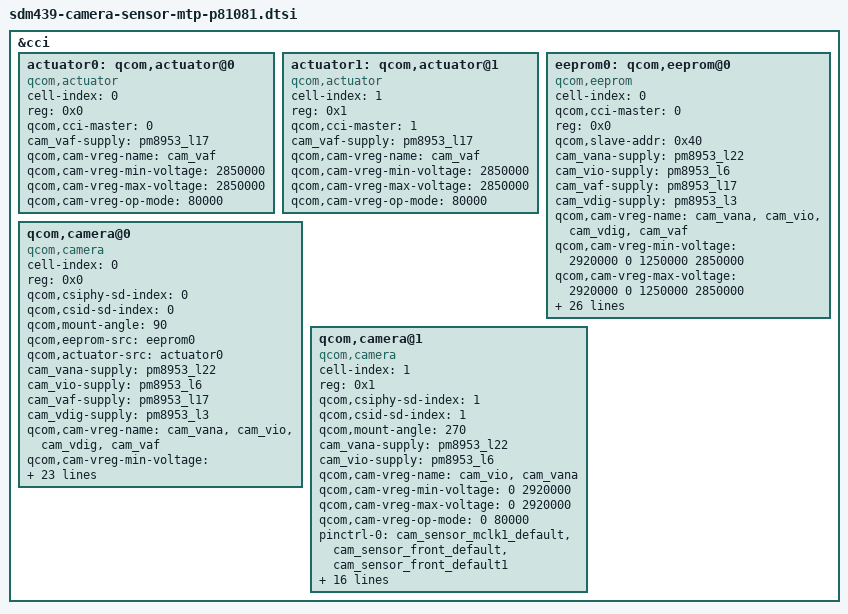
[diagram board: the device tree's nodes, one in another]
/*
 * Copyright (c) 2015-2016, 2018, The Linux Foundation. All rights reserved.
 *
 * This program is free software; you can redistribute it and/or modify
 * it under the terms of the GNU General Public License version 2 and
 * only version 2 as published by the Free Software Foundation.
 *
 * This program is distributed in the hope that it will be useful,
 * but WITHOUT ANY WARRANTY; without even the implied warranty of
 * MERCHANTABILITY or FITNESS FOR A PARTICULAR PURPOSE.  See the
 * GNU General Public License for more details.
 */

#include <dt-bindings/clock/msm-clocks-8952.h>

&cci {
	actuator0: qcom,actuator@0 {
		cell-index = <0>;
		reg = <0x0>;
		compatible = "qcom,actuator";
		qcom,cci-master = <0>;
		cam_vaf-supply = <&pm8953_l17>;
		qcom,cam-vreg-name = "cam_vaf";
		qcom,cam-vreg-min-voltage = <2850000>;
		qcom,cam-vreg-max-voltage = <2850000>;
		qcom,cam-vreg-op-mode = <80000>;
	};

	actuator1: qcom,actuator@1 {
		cell-index = <1>;
		reg = <0x1>;
		compatible = "qcom,actuator";
		qcom,cci-master = <1>;
		cam_vaf-supply = <&pm8953_l17>;
		qcom,cam-vreg-name = "cam_vaf";
		qcom,cam-vreg-min-voltage = <2850000>;
		qcom,cam-vreg-max-voltage = <2850000>;
		qcom,cam-vreg-op-mode = <80000>;
	};

	eeprom0: qcom,eeprom@0 {
		cell-index = <0>;
		compatible = "qcom,eeprom";
		qcom,cci-master = <0>;
		reg = <0x0>;
		qcom,slave-addr = <0x40>;
		cam_vana-supply = <&pm8953_l22>;
		cam_vio-supply = <&pm8953_l6>;
		cam_vaf-supply = <&pm8953_l17>;
		cam_vdig-supply = <&pm8953_l3>;
		qcom,cam-vreg-name = "cam_vana",
			"cam_vio", "cam_vdig", "cam_vaf";
		qcom,cam-vreg-min-voltage = <2920000 0 1250000 2850000>;
		qcom,cam-vreg-max-voltage = <2920000 0 1250000 2850000>;
		qcom,cam-vreg-op-mode = <80000 0 200000 100000>;
		pinctrl-names = "cam_default", "cam_suspend";
		pinctrl-0 = <&cam_sensor_mclk0_default
				&cam_sensor_rear_reset
			&cam_sensor_rear_vana>;
		pinctrl-1 = <&cam_sensor_mclk0_sleep
			&cam_sensor_rear_reset_sleep
			&cam_sensor_rear_vana_sleep>;
		gpios = <&tlmm 26 0>,
			<&tlmm 36 0>,
			<&tlmm 20 0>;
		qcom,gpio-reset = <1>;
		qcom,gpio-vana = <2>;
		qcom,gpio-req-tbl-num = <0 1 2>;
		qcom,gpio-req-tbl-flags = <1 0 0>;
		qcom,gpio-req-tbl-label = "CAMIF_MCLK0",
			"CAM_RESET0",
			"CAM_STANDBY0";
		qcom,cam-power-seq-type = "sensor_vreg", "sensor_vreg", "sensor_gpio" , "sensor_gpio" ,"sensor_clk", "sensor_gpio", "sensor_gpio";
		qcom,cam-power-seq-val = "cam_vana", "cam_gpio_vdig", "sensor_gpio_reset","sensor_gpio_standby", "sensor_cam_mclk", "sensor_gpio_reset","sensor_gpio_standby";
		qcom,cam-power-seq-cfg-val = <0 0 0 0 24000000 1 1>;
		qcom,cam-power-seq-delay = <0 0 1 1 5 5 5>;
		status = "ok";
		clocks = <&clock_gcc clk_mclk0_clk_src>,
			<&clock_gcc clk_gcc_camss_mclk0_clk>;
		clock-names = "cam_src_clk", "cam_clk";
		qcom,clock-rates = <24000000 0>;
	};
	qcom,camera@0 {
		cell-index = <0>;
		compatible = "qcom,camera";
		reg = <0x0>;
		qcom,csiphy-sd-index = <0>;
		qcom,csid-sd-index = <0>;
		qcom,mount-angle = <90>;
		//qcom,led-flash-src = <&led_flash0>;
		qcom,eeprom-src = <&eeprom0>;
		qcom,actuator-src = <&actuator0>;
		cam_vana-supply = <&pm8953_l22>;
		cam_vio-supply = <&pm8953_l6>;
		cam_vaf-supply = <&pm8953_l17>;
		cam_vdig-supply = <&pm8953_l3>;
		qcom,cam-vreg-name = "cam_vana",
			"cam_vio","cam_vdig", "cam_vaf";
		qcom,cam-vreg-min-voltage = <2920000 0 1250000 2850000>;
		qcom,cam-vreg-max-voltage = <2920000 0 1250000 2850000>;
		qcom,cam-vreg-op-mode = <80000 0 200000 100000>;
		pinctrl-names = "cam_default", "cam_suspend";
		pinctrl-0 = <&cam_sensor_mclk0_default
			&cam_sensor_rear_reset
			&cam_sensor_rear_standby>;
		pinctrl-1 = <&cam_sensor_mclk0_sleep
			&cam_sensor_rear_reset_sleep
			&cam_sensor_rear_standby_sleep>;
		gpios = <&tlmm 26 0>,
			<&tlmm 36 0>,
		       <&tlmm 20 0>;
		qcom,gpio-reset = <1>;
		qcom,gpio-standby = <2>;
		qcom,gpio-req-tbl-num = <0 1 2>;
		qcom,gpio-req-tbl-flags = <1 0 0>;
		qcom,gpio-req-tbl-label = "CAMIF_MCLK0",
			"CAM_RESET0",
			"CAM_STANDBY0";
		qcom,sensor-position = <0>;
		qcom,sensor-mode = <0>;
		qcom,cci-master = <0>;
		status = "ok";
		clocks = <&clock_gcc clk_mclk0_clk_src>,
				<&clock_gcc clk_gcc_camss_mclk0_clk>;
		clock-names = "cam_src_clk", "cam_clk";
		qcom,clock-rates = <24000000 0>;
	};
	qcom,camera@1 {
		cell-index = <1>;
		compatible = "qcom,camera";
		reg = <0x1>;
		qcom,csiphy-sd-index = <1>;
		qcom,csid-sd-index = <1>;
		qcom,mount-angle = <270>;
		cam_vana-supply = <&pm8953_l22>;
		cam_vio-supply = <&pm8953_l6>;
		qcom,cam-vreg-name = "cam_vio", "cam_vana";
		qcom,cam-vreg-min-voltage = <0 2920000>;
		qcom,cam-vreg-max-voltage = <0 2920000>;
		qcom,cam-vreg-op-mode = <0 80000>;
		pinctrl-names = "cam_default", "cam_suspend";
		pinctrl-0 = <&cam_sensor_mclk1_default
				&cam_sensor_front_default
				&cam_sensor_front_default1>;
		pinctrl-1 = <&cam_sensor_mclk1_sleep
				&cam_sensor_front_sleep
				&cam_sensor_front_sleep1>;
		gpios = <&tlmm 27 0>,
			<&tlmm 38 0>,
			<&tlmm 128 0>;
		qcom,gpio-reset = <1>;
		qcom,gpio-standby = <2>;
		qcom,gpio-req-tbl-num = <0 1 2>;
		qcom,gpio-req-tbl-flags = <1 0 0>;
		qcom,gpio-req-tbl-label = "CAMIF_MCLK1",
			"CAM_RESET1",
			"CAM_STANDBY1";
		qcom,sensor-position = <0x100>;
		qcom,sensor-mode = <1>;
		qcom,cci-master = <1>;
		clocks = <&clock_gcc clk_mclk1_clk_src>,
				<&clock_gcc clk_gcc_camss_mclk1_clk>;
		clock-names = "cam_src_clk", "cam_clk";
		qcom,clock-rates = <24000000 0>;
	};
};
